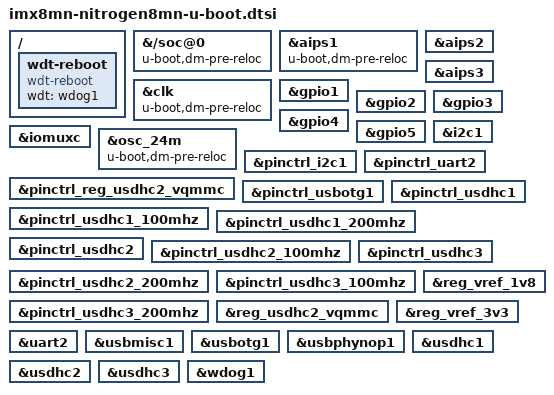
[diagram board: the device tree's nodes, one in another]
// SPDX-License-Identifier: GPL-2.0+
/*
 * Copyright 2019 NXP
 */

/ {
	wdt-reboot {
		compatible = "wdt-reboot";
		wdt = <&wdog1>;
		u-boot,dm-spl;
	};
};

&{/soc@0} {
	u-boot,dm-pre-reloc;
	u-boot,dm-spl;
};

&aips1 {
	u-boot,dm-spl;
	u-boot,dm-pre-reloc;
};

&aips2 {
	u-boot,dm-spl;
};

&aips3 {
	u-boot,dm-spl;
};

&clk {
	u-boot,dm-spl;
	u-boot,dm-pre-reloc;
	/delete-property/ assigned-clocks;
	/delete-property/ assigned-clock-parents;
	/delete-property/ assigned-clock-rates;
};

&gpio1 {
	u-boot,dm-spl;
};

&gpio2 {
	u-boot,dm-spl;
};

&gpio3 {
	u-boot,dm-spl;
};

&gpio4 {
	u-boot,dm-spl;
};

&gpio5 {
	u-boot,dm-spl;
};

&i2c1 {
	u-boot,dm-spl;
};

&iomuxc {
	u-boot,dm-spl;
};

&osc_24m {
	u-boot,dm-spl;
	u-boot,dm-pre-reloc;
};

&pinctrl_i2c1 {
	u-boot,dm-spl;
};

&pinctrl_reg_usdhc2_vqmmc {
	u-boot,dm-spl;
};

&pinctrl_uart2 {
	u-boot,dm-spl;
};

&pinctrl_usbotg1 {
	u-boot,dm-spl;
};

&pinctrl_usdhc1 {
	u-boot,dm-spl;
};

&pinctrl_usdhc1_100mhz {
	u-boot,dm-spl;
};

&pinctrl_usdhc1_200mhz {
	u-boot,dm-spl;
};

&pinctrl_usdhc2 {
	u-boot,dm-spl;
};

&pinctrl_usdhc2_100mhz {
	u-boot,dm-spl;
};

&pinctrl_usdhc2_200mhz {
	u-boot,dm-spl;
};

&pinctrl_usdhc3 {
	u-boot,dm-spl;
};

&pinctrl_usdhc3_100mhz {
	u-boot,dm-spl;
};

&pinctrl_usdhc3_200mhz {
	u-boot,dm-spl;
};

&reg_usdhc2_vqmmc {
	u-boot,dm-spl;
};

&reg_vref_1v8 {
	u-boot,dm-spl;
};

&reg_vref_3v3 {
	u-boot,dm-spl;
};

&uart2 {
	u-boot,dm-spl;
};

&usbmisc1 {
	u-boot,dm-spl;
};

&usbotg1 {
	u-boot,dm-spl;
};

&usbphynop1 {
	u-boot,dm-spl;
};

&usdhc1 {
	u-boot,dm-spl;
};

&usdhc2 {
	u-boot,dm-spl;
};

&usdhc3 {
	u-boot,dm-spl;
};

&wdog1 {
	u-boot,dm-spl;
};
